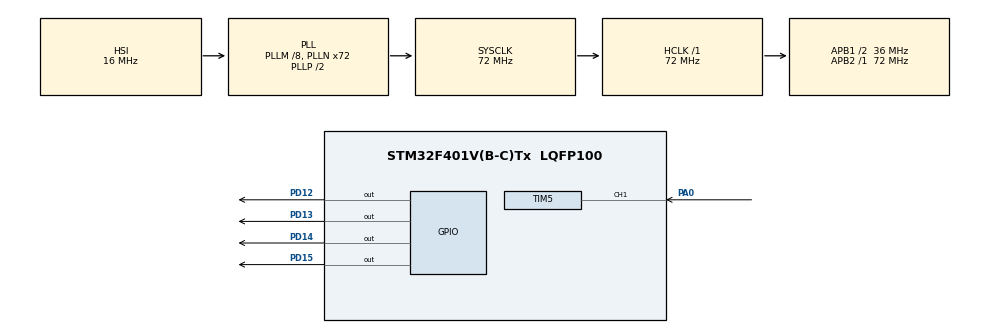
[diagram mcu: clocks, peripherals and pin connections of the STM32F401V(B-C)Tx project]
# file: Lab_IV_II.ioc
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Mcu.Family=STM32F4
Mcu.Name=STM32F401V(B-C)Tx
Mcu.Package=LQFP100
NVIC.PriorityGroup=NVIC_PRIORITYGROUP_0
NVIC.TIM3_IRQn=true\:0\:0\:false\:false\:true\:true\:true\:true
NVIC.TIM5_IRQn=true\:0\:0\:false\:false\:true\:true\:true\:true
PA0-WKUP.Signal=S_TIM5_CH1
PD12.Signal=GPIO_Output
PD13.Signal=GPIO_Output
PD14.Signal=GPIO_Output
PD15.Signal=GPIO_Output
ProjectManager.HeapSize=0x200
ProjectManager.StackSize=0x400
ProjectManager.TargetToolchain=STM32CubeIDE
RCC.48MHZClocksFreq_Value=20571428.57142857
RCC.AHBFreq_Value=72000000
RCC.APB1CLKDivider=RCC_HCLK_DIV2
RCC.APB1Freq_Value=36000000
RCC.APB1TimFreq_Value=72000000
RCC.APB2Freq_Value=72000000
RCC.APB2TimFreq_Value=72000000
RCC.CortexFreq_Value=72000000
RCC.HCLKFreq_Value=72000000
RCC.HSE_VALUE=8000000
RCC.HSI_VALUE=16000000
RCC.PLLM=8
RCC.PLLN=72
RCC.PLLQ=7
RCC.SYSCLKFreq_VALUE=72000000
RCC.SYSCLKSource=RCC_SYSCLKSOURCE_PLLCLK
RCC.VCOOutputFreq_Value=144000000
SH.S_TIM5_CH1.0=TIM5_CH1,Input_Capture1_from_TI1
TIM3.Period=4000-1
TIM3.Prescaler=36000-1
TIM5.Channel-Input_Capture1_from_TI1=TIM_CHANNEL_1
TIM5.ICFilter_CH1=15
TIM5.ICPolarity_CH1=TIM_INPUTCHANNELPOLARITY_FALLING
TIM5.Period=12000-1
TIM5.Prescaler=36000-1
VP_TIM3_VS_ClockSourceINT.Mode=Internal
VP_TIM5_VS_ClockSourceINT.Mode=Internal
board=STM32F401C-DISCO

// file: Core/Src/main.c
/* USER CODE BEGIN Header */
/**
  ******************************************************************************
  * @file           : main.c
  * @brief          : Main program body
  ******************************************************************************
  * @attention
  *
  * Copyright (c) 2023 STMicroelectronics.
  * All rights reserved.
  *
  * This software is licensed under terms that can be found in the LICENSE file
  * in the root directory of this software component.
  * If no LICENSE file comes with this software, it is provided AS-IS.
  *
  ******************************************************************************
  */
/* USER CODE END Header */
#include "main.h"

/* USER CODE BEGIN Includes */
uint32_t inputCaptureVal;
/* USER CODE END Includes */

TIM_HandleTypeDef htim3;
TIM_HandleTypeDef htim5;

void SystemClock_Config(void);
static void MX_GPIO_Init(void);
static void MX_TIM5_Init(void);
static void MX_TIM3_Init(void);

int main(void)
{

  /* MCU Configuration--------------------------------------------------------*/

  /* Reset of all peripherals, Initializes the Flash interface and the Systick. */
  HAL_Init();

  /* Configure the system clock */
  SystemClock_Config();

  /* Initialize all configured peripherals */
  MX_GPIO_Init();
  MX_TIM5_Init();
  MX_TIM3_Init();
  /* USER CODE BEGIN 2 */
  HAL_TIM_IC_Start_IT(&htim5, TIM_CHANNEL_1);
  HAL_TIM_Base_Start_IT(&htim3);
  /* USER CODE END 2 */

  /* Infinite loop */
  /* USER CODE BEGIN WHILE */
  while (1)
  {
	  HAL_TIM_Base_Start_IT(&htim3);
    /* USER CODE END WHILE */

  }
}

void HAL_TIM_IC_CaptureCallback(TIM_HandleTypeDef * htim)
{
	UNUSED(htim);
	if(htim->Instance == TIM5)
	{
		inputCaptureVal = __HAL_TIM_GET_COUNTER(htim);
		__HAL_TIM_SetCounter(htim, 0);

		if(inputCaptureVal <= 4000)
		{
			HAL_GPIO_WritePin(GPIOD, GPIO_PIN_15, RESET);
			HAL_GPIO_WritePin(GPIOD, GPIO_PIN_14, RESET);
			HAL_GPIO_WritePin(GPIOD, GPIO_PIN_15, SET);
		}
		if((inputCaptureVal > 4000) && (inputCaptureVal <= 8000))
		{
			HAL_GPIO_WritePin(GPIOD, GPIO_PIN_13, RESET);
			HAL_GPIO_WritePin(GPIOD, GPIO_PIN_14, SET);
			HAL_GPIO_WritePin(GPIOD, GPIO_PIN_15, SET);
		}
		if(inputCaptureVal > 8000)
		{
			HAL_GPIO_WritePin(GPIOD, GPIO_PIN_13, SET);
			HAL_GPIO_WritePin(GPIOD, GPIO_PIN_14, SET);
			HAL_GPIO_WritePin(GPIOD, GPIO_PIN_15, SET);
		}

		inputCaptureVal = 0;
	}
}

void SystemClock_Config(void)
{
  RCC_OscInitTypeDef RCC_OscInitStruct = {0};
  RCC_ClkInitTypeDef RCC_ClkInitStruct = {0};

  /** Configure the main internal regulator output voltage
  */
  __HAL_RCC_PWR_CLK_ENABLE();
  __HAL_PWR_VOLTAGESCALING_CONFIG(PWR_REGULATOR_VOLTAGE_SCALE2);

  /** Initializes the RCC Oscillators according to the specified parameters
  * in the RCC_OscInitTypeDef structure.
  */
  RCC_OscInitStruct.OscillatorType = RCC_OSCILLATORTYPE_HSI;
  RCC_OscInitStruct.HSIState = RCC_HSI_ON;
  RCC_OscInitStruct.HSICalibrationValue = RCC_HSICALIBRATION_DEFAULT;
  RCC_OscInitStruct.PLL.PLLState = RCC_PLL_ON;
  RCC_OscInitStruct.PLL.PLLSource = RCC_PLLSOURCE_HSI;
  RCC_OscInitStruct.PLL.PLLM = 8;
  RCC_OscInitStruct.PLL.PLLN = 72;
  RCC_OscInitStruct.PLL.PLLP = RCC_PLLP_DIV2;
  RCC_OscInitStruct.PLL.PLLQ = 7;
  if (HAL_RCC_OscConfig(&RCC_OscInitStruct) != HAL_OK)
  {
    Error_Handler();
  }

  /** Initializes the CPU, AHB and APB buses clocks
  */
  RCC_ClkInitStruct.ClockType = RCC_CLOCKTYPE_HCLK|RCC_CLOCKTYPE_SYSCLK
                              |RCC_CLOCKTYPE_PCLK1|RCC_CLOCKTYPE_PCLK2;
  RCC_ClkInitStruct.SYSCLKSource = RCC_SYSCLKSOURCE_PLLCLK;
  RCC_ClkInitStruct.AHBCLKDivider = RCC_SYSCLK_DIV1;
  RCC_ClkInitStruct.APB1CLKDivider = RCC_HCLK_DIV2;
  RCC_ClkInitStruct.APB2CLKDivider = RCC_HCLK_DIV1;

  if (HAL_RCC_ClockConfig(&RCC_ClkInitStruct, FLASH_LATENCY_2) != HAL_OK)
  {
    Error_Handler();
  }
}

static void MX_TIM3_Init(void)
{

  TIM_ClockConfigTypeDef sClockSourceConfig = {0};
  TIM_MasterConfigTypeDef sMasterConfig = {0};

  htim3.Instance = TIM3;
  htim3.Init.Prescaler = 36000-1;
  htim3.Init.CounterMode = TIM_COUNTERMODE_UP;
  htim3.Init.Period = 4000-1;
  htim3.Init.ClockDivision = TIM_CLOCKDIVISION_DIV1;
  htim3.Init.AutoReloadPreload = TIM_AUTORELOAD_PRELOAD_DISABLE;
  if (HAL_TIM_Base_Init(&htim3) != HAL_OK)
  {
    Error_Handler();
  }
  sClockSourceConfig.ClockSource = TIM_CLOCKSOURCE_INTERNAL;
  if (HAL_TIM_ConfigClockSource(&htim3, &sClockSourceConfig) != HAL_OK)
  {
    Error_Handler();
  }
  sMasterConfig.MasterOutputTrigger = TIM_TRGO_RESET;
  sMasterConfig.MasterSlaveMode = TIM_MASTERSLAVEMODE_DISABLE;
  if (HAL_TIMEx_MasterConfigSynchronization(&htim3, &sMasterConfig) != HAL_OK)
  {
    Error_Handler();
  }

}

static void MX_TIM5_Init(void)
{

  TIM_ClockConfigTypeDef sClockSourceConfig = {0};
  TIM_MasterConfigTypeDef sMasterConfig = {0};
  TIM_IC_InitTypeDef sConfigIC = {0};

  htim5.Instance = TIM5;
  htim5.Init.Prescaler = 36000-1;
  htim5.Init.CounterMode = TIM_COUNTERMODE_UP;
  htim5.Init.Period = 12000-1;
  htim5.Init.ClockDivision = TIM_CLOCKDIVISION_DIV1;
  htim5.Init.AutoReloadPreload = TIM_AUTORELOAD_PRELOAD_DISABLE;
  if (HAL_TIM_Base_Init(&htim5) != HAL_OK)
  {
    Error_Handler();
  }
  sClockSourceConfig.ClockSource = TIM_CLOCKSOURCE_INTERNAL;
  if (HAL_TIM_ConfigClockSource(&htim5, &sClockSourceConfig) != HAL_OK)
  {
    Error_Handler();
  }
  if (HAL_TIM_IC_Init(&htim5) != HAL_OK)
  {
    Error_Handler();
  }
  sMasterConfig.MasterOutputTrigger = TIM_TRGO_RESET;
  sMasterConfig.MasterSlaveMode = TIM_MASTERSLAVEMODE_DISABLE;
  if (HAL_TIMEx_MasterConfigSynchronization(&htim5, &sMasterConfig) != HAL_OK)
  {
    Error_Handler();
  }
  sConfigIC.ICPolarity = TIM_INPUTCHANNELPOLARITY_FALLING;
  sConfigIC.ICSelection = TIM_ICSELECTION_DIRECTTI;
  sConfigIC.ICPrescaler = TIM_ICPSC_DIV1;
  sConfigIC.ICFilter = 15;
  if (HAL_TIM_IC_ConfigChannel(&htim5, &sConfigIC, TIM_CHANNEL_1) != HAL_OK)
  {
    Error_Handler();
  }

}

static void MX_GPIO_Init(void)
{
  GPIO_InitTypeDef GPIO_InitStruct = {0};

  /* GPIO Ports Clock Enable */
  __HAL_RCC_GPIOA_CLK_ENABLE();
  __HAL_RCC_GPIOD_CLK_ENABLE();

  /*Configure GPIO pin Output Level */
  HAL_GPIO_WritePin(GPIOD, GPIO_PIN_12|GPIO_PIN_13|GPIO_PIN_14|GPIO_PIN_15, GPIO_PIN_RESET);

  /*Configure GPIO pins : PD12 PD13 PD14 PD15 */
  GPIO_InitStruct.Pin = GPIO_PIN_12|GPIO_PIN_13|GPIO_PIN_14|GPIO_PIN_15;
  GPIO_InitStruct.Mode = GPIO_MODE_OUTPUT_PP;
  GPIO_InitStruct.Pull = GPIO_NOPULL;
  GPIO_InitStruct.Speed = GPIO_SPEED_FREQ_LOW;
  HAL_GPIO_Init(GPIOD, &GPIO_InitStruct);

}

void Error_Handler(void)
{
  __disable_irq();
  while (1)
  {
  }
}
